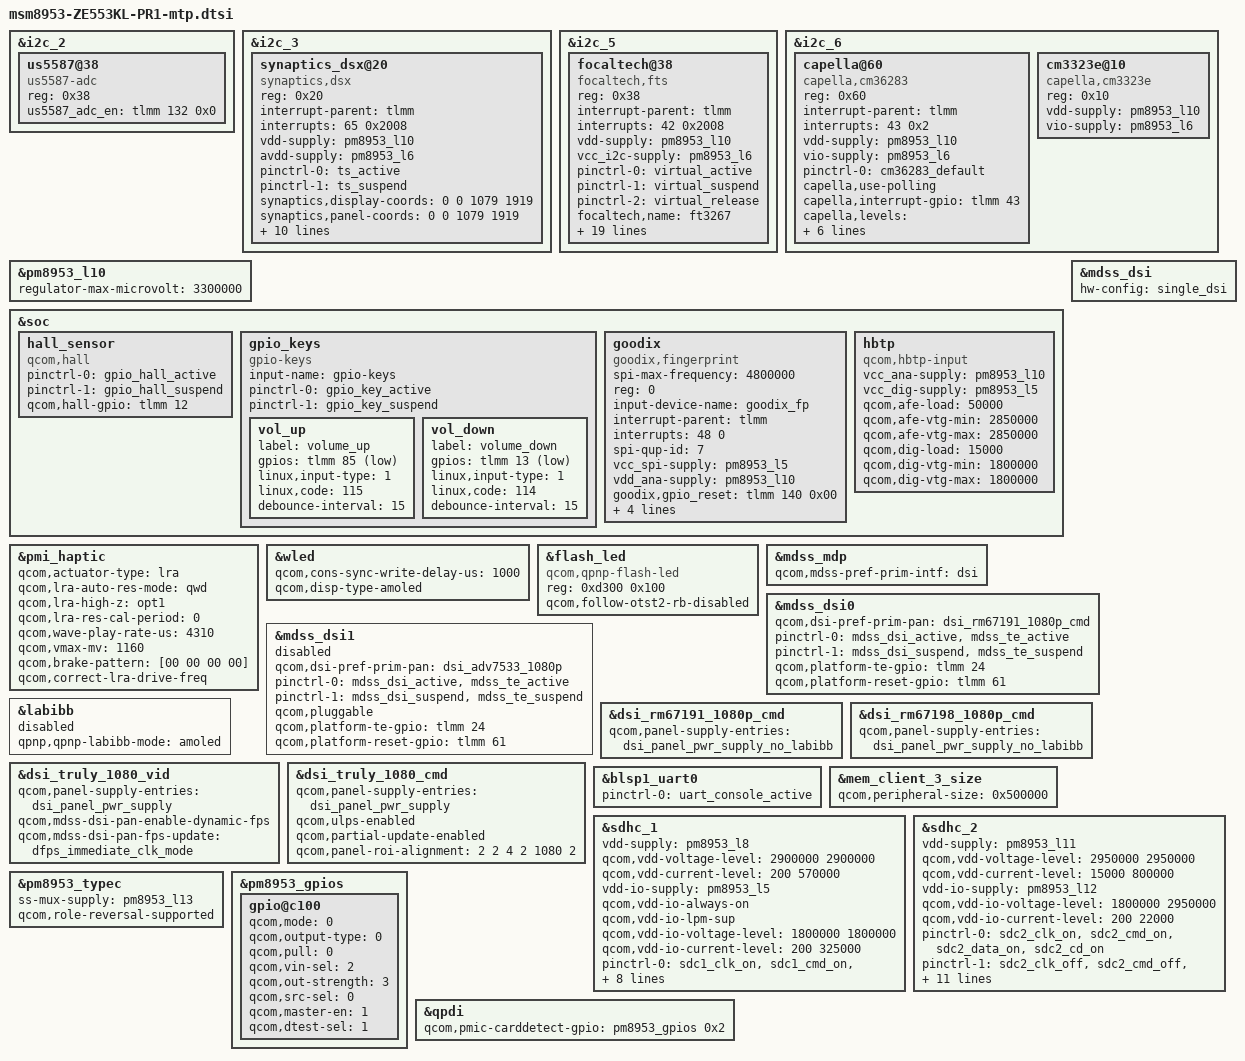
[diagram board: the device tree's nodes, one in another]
/*
 * Copyright (c) 2015-2017, The Linux Foundation. All rights reserved.
 *
 * This program is free software; you can redistribute it and/or modify
 * it under the terms of the GNU General Public License version 2 and
 * only version 2 as published by the Free Software Foundation.
 *
 * This program is distributed in the hope that it will be useful,
 * but WITHOUT ANY WARRANTY; without even the implied warranty of
 * MERCHANTABILITY or FITNESS FOR A PARTICULAR PURPOSE.  See the
 * GNU General Public License for more details.
 */

#include "msm8953-ZE553KL-PR1-pinctrl.dtsi"
#include "msm8953-ZE553KL-audio-mtp.dtsi"
#include "msm8953-ZE553KL-camera-sensor-mtp.dtsi"

&i2c_2 {		
	us5587@38{
		compatible = "us5587-adc";
		reg = <0x38>;
		us5587_adc_en = < &tlmm 132 0x0>;
		};
};

&i2c_3 { /* BLSP1 QUP3 */

	synaptics_dsx@20 {
		compatible = "synaptics,dsx";
		reg = <0x20>;
		interrupt-parent = <&tlmm>;
		interrupts = <65 0x2008>;
		vdd-supply = <&pm8953_l10>;
		avdd-supply = <&pm8953_l6>;
		pinctrl-names = "pmx_ts_active", "pmx_ts_suspend";
		pinctrl-0 = <&ts_active>;
		pinctrl-1 = <&ts_suspend>;
		synaptics,display-coords = <0 0 1079 1919>;
		synaptics,panel-coords = <0 0 1079 1919>;
		synaptics,reset-gpio = <&tlmm 16 0x0>;
		synaptics,irq-gpio = <&tlmm 65 0x2008>;
		synaptics,disable-gpios;
		synaptics,power-delay-ms = <200>;
		synaptics,reset-delay-ms = <200>;
		synaptics,reset-on-state = <0>;
		synaptics,reset-active-ms = <20>;
		synaptics,ub-i2c-addr = <0x70>;
		synaptics,fw-name = "PR2507195-45440006-S3508R_111616.img";
		/* uncomment and update line below as appropriate if there are 0D buttons */
		//synaptics,cap-button-codes = <158 102 139>;
		/* uncomment and update lines below as appropriate if there are virtual buttons */
		/* synaptics,vir-button-codes = <102 100 900 100 60 158 300 900 100 60>; */
		/* synaptics,max-y-for-2d = <800>; */
	};
};

&i2c_5 { 
	focaltech@38 {
		compatible = "focaltech,fts";
		reg = <0x38>;
		interrupt-parent = <&tlmm>;
		interrupts = <42 0x2008>;
		vdd-supply = <&pm8953_l10>;
		vcc_i2c-supply = <&pm8953_l6>;
		pinctrl-names = "pmx_virtual_active", "pmx_virtual_suspend","pmx_virtual_release";
		pinctrl-0 = <&virtual_active>;
		pinctrl-1 = <&virtual_suspend>;
		pinctrl-2 = <&virtual_release>;
		focaltech,name = "ft3267";
		focaltech,family-id = <0x64>;
		focaltech,reset-gpio = <&tlmm 46 0x0>;
		focaltech,irq-gpio = <&tlmm 42 0x2008>;
 		focaltech,display-coords = <0 0 1080 1920>;
 		focaltech,panel-coords = <0 0 1080 1920>;
		focaltech,no-force-update;
		focaltech,i2c-pull-up;
		focaltech,group-id = <1>;
		focaltech,hard-reset-delay-ms = <20>;
		focaltech,soft-reset-delay-ms = <200>;
		focaltech,num-max-touches = <5>;
		focaltech,fw-delay-aa-ms = <30>;
		focaltech,fw-delay-55-ms = <30>;
		focaltech,fw-upgrade-id1 = <0x79>;
		focaltech,fw-upgrade-id2 = <0x18>;
		focaltech,fw-delay-readid-ms = <10>;
		focaltech,fw-delay-era-flsh-ms = <2000>;
		focaltech,fw-auto-cal;
		focaltech,ignore-id-check;
	};
};

&i2c_6 { /* BLSP2 QUP2 */
 	capella@60 {
 		compatible = "capella,cm36283";
 		reg = <0x60>;
 		interrupt-parent = <&tlmm>;
 		interrupts = <43 0x2>;
 		vdd-supply = <&pm8953_l10>;
 		vio-supply = <&pm8953_l6>;
 		pinctrl-names = "default";
 		pinctrl-0 = <&cm36283_default>;
 		capella,use-polling;
 		capella,interrupt-gpio = <&tlmm 43 0x2>;
 		capella,levels = <0x0A 0xA0 0xE1 0x140 0x280 0x500 0xA28 0x16A8 0x1F40 0x2800>;
 		capella,ps_close_thd_set = <0x200>;
 		capella,ps_away_thd_set = <0x100>;
 		capella,ls_cmd = <0x44>; /* ALS_IT=160ms, INT_PERS=2*/
 		capella,ps_conf1_val = <0x0006>;
 		capella,ps_conf3_val = <0x3010>;
	};

	cm3323e@10{
		compatible = "capella,cm3323e";
		reg = <0x10>;
		vdd-supply = <&pm8953_l10>;
		vio-supply = <&pm8953_l6>;
	};
};

&pm8953_l10 {
	regulator-max-microvolt = <3300000>;
};

&soc {
	hall_sensor {
		compatible = "qcom,hall";
		pinctrl-names = "hall_gpio_high","hall_gpio_low";
		pinctrl-0 = <&gpio_hall_active>;
		pinctrl-1 = <&gpio_hall_suspend>;
		qcom,hall-gpio = <&tlmm 12 0x0>;
	};

	gpio_keys {
		compatible = "gpio-keys";
		input-name = "gpio-keys";
		pinctrl-names = "tlmm_gpio_key_active","tlmm_gpio_key_suspend";
		pinctrl-0 = <&gpio_key_active>;
		pinctrl-1 = <&gpio_key_suspend>;

		vol_up {
			label = "volume_up";
			gpios = <&tlmm 85 0x1>;
			linux,input-type = <1>;
			linux,code = <115>;
			debounce-interval = <15>;
		};

		vol_down {
			label = "volume_down";
			gpios = <&tlmm 13 0x1>;
			linux,input-type = <1>;
			linux,code = <114>;
			debounce-interval = <15>;
		};

	};

	goodix {
		compatible = "goodix,fingerprint";
	 	spi-max-frequency = <4800000>;
	 	reg = <0>;
	 	input-device-name = "goodix_fp";
	 	interrupt-parent = <&tlmm>;
	 	interrupts = <48 0>;
	 	spi-qup-id = <7>;
 	
	 	vcc_spi-supply  = <&pm8953_l5>;
	 	vdd_ana-supply  = <&pm8953_l10>;

		//goodix,gpio_pwr = <&tlmm 129 0x00>;

		goodix,gpio_reset = <&tlmm 140 0x00>;
	 	goodix,gpio_irq = <&tlmm 48 0x00>;

		pinctrl-names = "goodix_irq_active";
	 	pinctrl-0 = <&goodix_irq_active>;

		clock-names = "iface_clk", "core_clk";
	 	clocks = <&clock_gcc clk_gcc_blsp2_ahb_clk>,
	 		 <&clock_gcc clk_gcc_blsp2_qup3_spi_apps_clk>;	
	 };

	hbtp {
		compatible = "qcom,hbtp-input";
		vcc_ana-supply = <&pm8953_l10>;
		vcc_dig-supply = <&pm8953_l5>;
		qcom,afe-load = <50000>;
		qcom,afe-vtg-min = <2850000>;
		qcom,afe-vtg-max = <2850000>;
		qcom,dig-load = <15000>;
		qcom,dig-vtg-min = <1800000>;
		qcom,dig-vtg-max = <1800000>;
	};
};

&pmi_haptic{
	qcom,actuator-type = "lra";
	qcom,lra-auto-res-mode="qwd";
	qcom,lra-high-z="opt1";
	qcom,lra-res-cal-period = <0>;
	qcom,wave-play-rate-us = <4310>;
	qcom,vmax-mv = <1160>;
	qcom,brake-pattern = [00 00 00 00];
	qcom,correct-lra-drive-freq;
};

&wled {
	qcom,cons-sync-write-delay-us = <1000>;
};

&flash_led {
	compatible = "qcom,qpnp-flash-led";
	reg = <0xd300 0x100>;
	qcom,follow-otst2-rb-disabled;
};

#include "msm8953-mdss-panels-ZE553KL.dtsi"

&mdss_mdp {
	qcom,mdss-pref-prim-intf = "dsi";
};

&mdss_dsi {
	hw-config = "single_dsi";
};

&mdss_dsi0 {
	qcom,dsi-pref-prim-pan = <&dsi_rm67191_1080p_cmd>;//ZE553KL panel+++
	pinctrl-names = "mdss_default", "mdss_sleep";
	pinctrl-0 = <&mdss_dsi_active &mdss_te_active>;
	pinctrl-1 = <&mdss_dsi_suspend &mdss_te_suspend>;

	qcom,platform-te-gpio = <&tlmm 24 0>;
	qcom,platform-reset-gpio = <&tlmm 61 0>;
	//qcom,platform-bklight-en-gpio = <&tlmm 59 0>;
};

&mdss_dsi1 {
	status = "disabled";
	qcom,dsi-pref-prim-pan = <&dsi_adv7533_1080p>;
	pinctrl-names = "mdss_default", "mdss_sleep";
	pinctrl-0 = <&mdss_dsi_active &mdss_te_active>;
	pinctrl-1 = <&mdss_dsi_suspend &mdss_te_suspend>;

	qcom,pluggable;
	qcom,platform-te-gpio = <&tlmm 24 0>;
	qcom,platform-reset-gpio = <&tlmm 61 0>;
	//qcom,platform-bklight-en-gpio = <&tlmm 59 0>;
};

&labibb {
	status = "disable";
	qpnp,qpnp-labibb-mode = "amoled";//ZE553KL panel+++
};

/*+++++++++ASUS ZE553KL Panel++++++++++*/
&wled {
  qcom,disp-type-amoled;
};

&dsi_rm67191_1080p_cmd {
	qcom,panel-supply-entries = <&dsi_panel_pwr_supply_no_labibb>;
};

&dsi_rm67198_1080p_cmd {
	qcom,panel-supply-entries = <&dsi_panel_pwr_supply_no_labibb>;
};
/*---------ASUS ZE553KL second Panel----------*/

&dsi_truly_1080_vid {
	qcom,panel-supply-entries = <&dsi_panel_pwr_supply>;
	qcom,mdss-dsi-pan-enable-dynamic-fps;
	qcom,mdss-dsi-pan-fps-update = "dfps_immediate_clk_mode";
};

&dsi_truly_1080_cmd {
	qcom,panel-supply-entries = <&dsi_panel_pwr_supply>;
	qcom,ulps-enabled;
	qcom,partial-update-enabled;
	qcom,panel-roi-alignment = <2 2 4 2 1080 2>;
};

&blsp1_uart0 {
	status = "ok";
	pinctrl-names = "default";
	pinctrl-0 = <&uart_console_active>;
};

&mem_client_3_size {
	qcom,peripheral-size = <0x500000>;
};

&sdhc_1 {
	/* device core power supply */
	vdd-supply = <&pm8953_l8>;
	qcom,vdd-voltage-level = <2900000 2900000>;
	qcom,vdd-current-level = <200 570000>;

	/* device communication power supply */
	vdd-io-supply = <&pm8953_l5>;
	qcom,vdd-io-always-on;
	qcom,vdd-io-lpm-sup;
	qcom,vdd-io-voltage-level = <1800000 1800000>;
	qcom,vdd-io-current-level = <200 325000>;

	pinctrl-names = "active", "sleep";
	pinctrl-0 = <&sdc1_clk_on &sdc1_cmd_on &sdc1_data_on  &sdc1_rclk_on>;
	pinctrl-1 = <&sdc1_clk_off &sdc1_cmd_off &sdc1_data_off &sdc1_rclk_off>;

	qcom,clk-rates = <400000 20000000 25000000 50000000 100000000 192000000
								384000000>;
	qcom,nonremovable;
	qcom,bus-speed-mode = "HS400_1p8v", "HS200_1p8v", "DDR_1p8v";

	status = "ok";
};

&sdhc_2 {
	/* device core power supply */
	vdd-supply = <&pm8953_l11>;
	qcom,vdd-voltage-level = <2950000 2950000>;
	qcom,vdd-current-level = <15000 800000>;

	/* device communication power supply */
	vdd-io-supply = <&pm8953_l12>;
	qcom,vdd-io-voltage-level = <1800000 2950000>;
	qcom,vdd-io-current-level = <200 22000>;

	pinctrl-names = "active", "sleep";
	pinctrl-0 = <&sdc2_clk_on &sdc2_cmd_on &sdc2_data_on &sdc2_cd_on>;
	pinctrl-1 = <&sdc2_clk_off &sdc2_cmd_off &sdc2_data_off>;

	#address-cells = <0>;
	interrupt-parent = <&sdhc_2>;
	interrupts = <0 1 2>;
	#interrupt-cells = <1>;
	interrupt-map-mask = <0xffffffff>;
	interrupt-map = <0 &intc 0 125 0
		1 &intc 0 221 0
		2 &tlmm 133 0>;
	interrupt-names = "hc_irq", "pwr_irq", "status_irq";
	cd-gpios = <&tlmm 133 0>;

	qcom,clk-rates = <400000 20000000 25000000 50000000 100000000
								200000000>;
	qcom,bus-speed-mode = "SDR12", "SDR25", "SDR50", "DDR50", "SDR104";

	status = "ok";
};

&pm8953_typec {
	ss-mux-supply = <&pm8953_l13>;
	qcom,role-reversal-supported;
	//qcom,ssmux-gpio = <&tlmm 139 GPIO_ACTIVE_HIGH>;
	//pinctrl-names = "default";
	//pinctrl-0 = <&typec_ssmux_config>;
};

&pm8953_gpios {
	/* GPIO 2 (NFC_CLK_REQ) */
	gpio@c100 {
		qcom,mode = <0>;
		qcom,output-type = <0>;
		qcom,pull = <0>;
		qcom,vin-sel = <2>;
		qcom,out-strength = <3>;
		qcom,src-sel = <0>;
		qcom,master-en = <1>;
		qcom,dtest-sel = <1>;
		status = "okay";
	};
};

&qpdi {
	qcom,pmic-carddetect-gpio = <&pm8953_gpios 0x2 0>;
};
